# max32665 register map
Vendor: Maxim-Integrated; Series: ARMCM3; File version: 1.0
CPU: CM4 r2p1, little endian, MPU, FPU, 3 interrupt priority bits
Registers are 32-bit, read-write, reset 0x0 unless marked. A register's access mark holds for its fields unless they carry their own. Offsets are from the block's base; [hi:lo] are bit positions; {n}, {i} and the like mark numbered series.

## ADC — 10-bit Analog to Digital Converter
Base 0x40035000
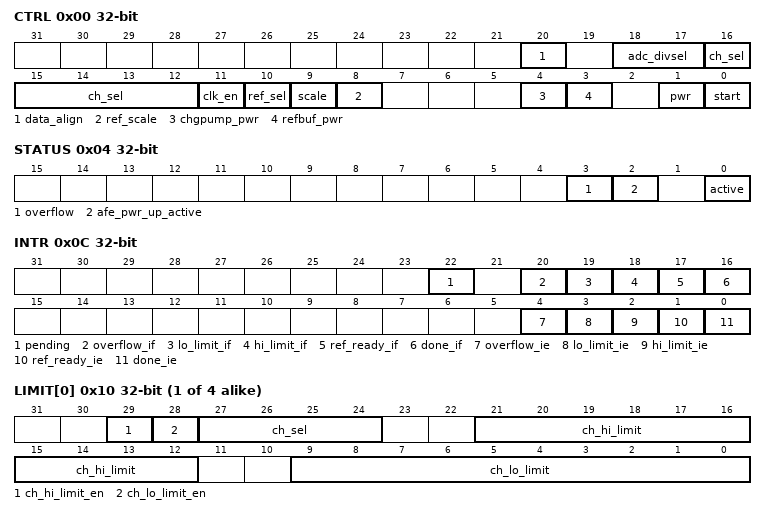
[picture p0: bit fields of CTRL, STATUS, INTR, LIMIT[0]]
0x00 CTRL — ADC Control
  [20] data_align — ADC Data Alignment Select
  [18:17] adc_divsel — Scales the external inputs, all inputs are scaled the same
    {v}=DIV{v+1} (v=0..3)
  [16:12] ch_sel — ADC Channel Select
    {v}=AIN{v} (v=0..7); 8=VcoreA; 9=VcoreB; 10=Vrxout; 11=Vtxout; 12=VddA; 13=VddB/4; 14=Vddio/4; 15=Vddioh/4; 16=VregI/4
  [11] clk_en — ADC Clock Enable
  [10] ref_sel — ADC Reference (VRef) Select (INTERNAL ONLY)
  [9] scale — ADC Scale
  [8] ref_scale — ADC Reference Scale
  [4] chgpump_pwr — ADC Charge Pump Power Up
  [3] refbuf_pwr — ADC Reference Buffer Power Up
  [1] pwr — ADC Power Up
  [0] start — Start ADC Conversion
0x04 STATUS — ADC Status
  [3] overflow ro — ADC Overflow
  [2] afe_pwr_up_active ro — AFE Power Up Delay Active
  [0] active ro — ADC Conversion In Progress
0x08 DATA — ADC Output Data
  [15:0] adc_data ro — ADC Converted Sample Data Output
0x0C INTR — ADC Interrupt Control Register
  [22] pending ro — ADC Interrupt Pending Status
  [20] overflow_if write-1-clears — ADC Overflow Interrupt Flag
  [19] lo_limit_if write-1-clears — ADC Lo Limit Monitor Interrupt Flag
  [18] hi_limit_if write-1-clears — ADC Hi Limit Monitor Interrupt Flag
  [17] ref_ready_if write-1-clears — ADC Reference Ready Interrupt Flag
  [16] done_if write-1-clears — ADC Done Interrupt Flag
  [4] overflow_ie — ADC Overflow Interrupt Enable
  [3] lo_limit_ie — ADC Lo Limit Monitor Interrupt Enable
  [2] hi_limit_ie — ADC Hi Limit Monitor Interrupt Enable
  [1] ref_ready_ie — ADC Reference Ready Interrupt Enable
  [0] done_ie — ADC Done Interrupt Enable
{0x10+4i} LIMIT[{i}] (i=0..3) — ADC Limit
  [29] ch_hi_limit_en — High Limit Monitoring Enable
  [28] ch_lo_limit_en — Low Limit Monitoring Enable
  [27:24] ch_sel — ADC Channel Select
  [21:12] ch_hi_limit — High Limit Threshold
  [9:0] ch_lo_limit — Low Limit Threshold

## MCR — Misc Control.
Base 0x40006C00
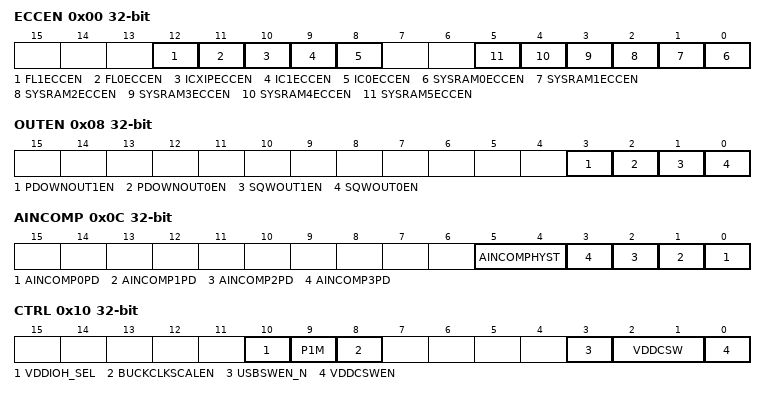
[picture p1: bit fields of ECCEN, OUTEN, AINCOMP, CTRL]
0x00 ECCEN — ECC Enable Register
  [all] fields
    0=dis (disabled.); 1=en (enabled.)
  [12] FL1ECCEN — Flash1 ECC Enable.
  [11] FL0ECCEN — Flash0 ECC Enable.
  [10] ICXIPECCEN — IcacheXIP ECC Enable.
  [9] IC1ECCEN — Icache1 ECC Enable.
  [8] IC0ECCEN — Icache0 ECC Enable.
  [n] SYSRAM{n}ECCEN (n=0..5) — ECC System RAM Enable.
0x04 HIRC96M — 96MHz Oscillator Trim Register
  [7:0] HIRC96MTR — Allows User to Trim 96MHz Oscillator
0x08 OUTEN — GPIOOUT_EN Function Enable Register
  [all] fields
    0=dis (disabled.); 1=en (enabled.)
  [3] PDOWNOUT1EN — Allows PDOWN on GPIO0_26
  [2] PDOWNOUT0EN — Allows PDOWN on GPIO0_18
  [1] SQWOUT1EN — Allows SQWOUT on GPIO0_27
  [0] SQWOUT0EN — Allows SQWOUT on GPIO0_19
0x0C AINCOMP — Comparator Power Control Register
  [5:4] AINCOMPHYST — Set Hysteresis on Analog Comparators
  [n] AINCOMP{n}PD (n=0..3) — Power Down AIN Comp{n}
    0=on (power on); 1=off (power off)
0x10 CTRL — Misc Power State Control Register
  [10] VDDIOH_SEL — Error! Description not Found!
  [9] P1M — Enable the Reset Pad Pull Up Resistors
    0=1m (1MOhm Pullup); 1=25k (25kOhm Pullup.)
  [8] BUCKCLKSCALEN — Allows Dynamic scaling of SIMO clock, reduces power in LP Modes
    0=dis (disabled.); 1=en (enabled.)
  [3] USBSWEN_N — USB Switch Control
    1=off (USB SW off in LP modes); 0=on (USB SW On)
  [2:1] VDDCSW — Controls switching of VCORE
  [0] VDDCSWEN — Allows switching VDDC from VCOREA to VCOREB
    0=dis (disabled.); 1=en (enabled.)

## AES_KEY — AES Keys.
Base 0x40005000
{0x0+0x80*i} aes_key{i} (i=0..3)

## EMCC — External Memory Cache Controller Registers.
Base 0x40033000
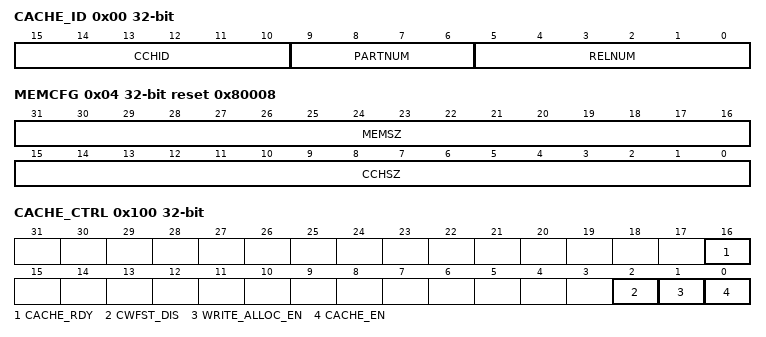
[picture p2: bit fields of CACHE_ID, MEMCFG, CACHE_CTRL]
0x00 CACHE_ID ro
  [15:10] CCHID — Cache ID. This field reflects the value of the C_ID_CACHEID configuration parameter.
  [9:6] PARTNUM — Part Number. This field reflects the value of C_ID_PART_NUMBER configuration parameter.
  [5:0] RELNUM — Release Number. Identifies the RTL release version.
0x04 MEMCFG ro reset 0x80008 — Memory Configuration Register.
  [31:16] MEMSZ — Main Memory Size. Indicates the total size, in units of 128 Kbytes, of code memory accessible to the cache controller.
  [15:0] CCHSZ — Cache Size. Indicates total size in Kbytes of cache.
0x100 CACHE_CTRL — Cache Control and Status Register.
  [16] CACHE_RDY — Cache Ready flag. Cleared by hardware when at any time the cache as a whole is invalidated (including a system reset). When this bit is 0, the cache is effectively in bypass mode (instruction fetches will come from main memory or from the line fill buffer). Set by hardware when the invalidate operation is complete and the cache is ready.
    0=notReady; 1=ready
  [2] CWFST_DIS — Critical word first and streaming disable. This bit only writeable while the cache is disabled.
    1=dis (Critical word first and streaming disabled.); 0=en (Critical word first and streaming enabled.)
  [1] WRITE_ALLOC_EN — Write Allocate Enable. This bit only writable while the cache is disabled.
    0=dis (Write-no-allocate.); 1=en (Write-allocate enabled.)
  [0] CACHE_EN — Cache Enable. Controls whether the cache is bypassed or is in use. Changing the state of this bit will cause the instruction cache to be flushed and its contents invalidated.
    0=dis (Cache Bypassed. Instruction data is stored in the line fill buffer but is not written to main cache memory array.); 1=en (Cache Enabled.)
0x700 INVALIDATE — Invalidate All Cache Contents. Any time this register location is written (regardless of the data value), the cache controller immediately begins invalidating the entire contents of the cache memory. The cache will be in bypass mode until the invalidate operation is complete. System software can examine the Cache Ready bit (CACHE_CTRL.CACHE_RDY) to determine when the invalidate operation is complete. Note that it is not necessary to disable the cache controller prior to beginning this operation. Reads from this register always return 0.
  [31:0] IA — Invalidate all cache contents.
